# ESP32-H4 register map
Vendor: ESPRESSIF SYSTEMS (SHANGHAI) CO., LTD.; Series: ESP32 H-Series; File version: 1
CPU: RV32IMAC r0p0, little endian, no MPU, no FPU, 0 interrupt priority bits
Address unit: 32 bits
Registers are 32-bit, read-write, reset 0x0 unless marked. A register's access mark holds for its fields unless they carry their own. Offsets are from the block's base; [hi:lo] are bit positions; {n}, {i} and the like mark numbered series.

## LP_AON — LP_AON Peripheral
Base 0x600B2800
{0x0+4i} STORE{i} (i=0..9) — store the software massege{i} in always-on field
  [31:0] LP_AON_STORE{i}
0x28 GPIO_MUX — select the lp io controlled by hp iomux or lp iomux
  [5:0] SEL — select the lp io 0~5 controlled by hp iomux or lp iomux 1: controlled by lp iomux 0: controlled by hp iomux
0x2C GPIO_HOLD0 — configure all io hold
  [31:0] GPIO_HOLD0 — configure io0~28 hold enable,when io in hold status, all io configure and output will be latch , input function is useful
0x30 GPIO_HOLD1 — reserved
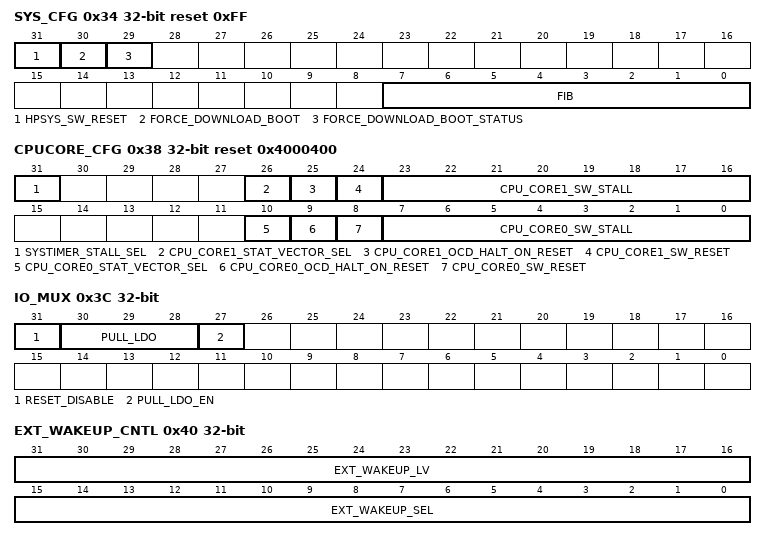
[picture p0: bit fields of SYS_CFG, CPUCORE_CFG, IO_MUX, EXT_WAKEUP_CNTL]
0x34 SYS_CFG access per field reset 0xFF — configure system register
  [31] HPSYS_SW_RESET wo — enable hp system reset by software or not 1: reset 0: no operation
  [30] FORCE_DOWNLOAD_BOOT rw — enable chip entry download mode or not 1: enable 0: no operation
  [29] FORCE_DOWNLOAD_BOOT_STATUS ro — get force download mode status
  [7:0] FIB ro — get fib reg information
0x38 CPUCORE_CFG access per field reset 0x4000400 — configure core reset register
  [31] SYSTIMER_STALL_SEL rw — selete which core run_stall to lp_timer 1: core1 0: core0
  [26] CPU_CORE1_STAT_VECTOR_SEL rw — configure core1 boot address 1: ROM 0: lp memory
  [25] CPU_CORE1_OCD_HALT_ON_RESET rw — reserved
  [24] CPU_CORE1_SW_RESET wo — enable core1 reset by software 1: reset 0: no operation
  [23:16] CPU_CORE1_SW_STALL rw — enable core 1 entry stall status 0x86: entry stall status Others : no operation
  [10] CPU_CORE0_STAT_VECTOR_SEL rw — configure core 0 boot address 1: ROM 0: lp memory
  [9] CPU_CORE0_OCD_HALT_ON_RESET rw — reserved
  [8] CPU_CORE0_SW_RESET wo — enable core 0 reset by software 1: reset 0: no operation
  [7:0] CPU_CORE0_SW_STALL rw — enable cpu 0 entry stall status 0x86: entry stall status Others : no operation
0x3C IO_MUX — configure hp iomux reset bypass
  [31] RESET_DISABLE — bypass hp iomux reset from hp system reset event 1: bypass 0: no operation
  [30:28] PULL_LDO — need_des
  [27] PULL_LDO_EN — need_des
0x40 EXT_WAKEUP_CNTL — configure alwayson external io wakeup
  [31:16] EXT_WAKEUP_LV — select external wakeup io level 1: io high level wakeup 0: io low level wakeup
  [15:0] EXT_WAKEUP_SEL — enable io0~15 bit map use to external wakeup 1: enable 0: disable
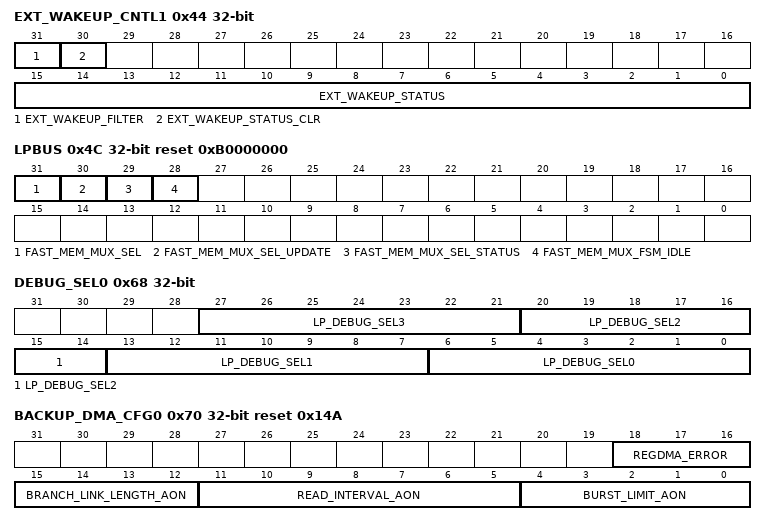
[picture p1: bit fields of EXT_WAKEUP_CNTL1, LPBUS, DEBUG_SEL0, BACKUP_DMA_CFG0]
0x44 EXT_WAKEUP_CNTL1 access per field — configure alwayson external io wakeup
  [31] EXT_WAKEUP_FILTER rw — enable external filter or not 1: enable 0: disable
  [30] EXT_WAKEUP_STATUS_CLR wo — clear external wakeup status 1: clear 0: no operation
  [15:0] EXT_WAKEUP_STATUS ro — get external wakeup status bitmap
0x48 USB — configure usb reset bypass
  [31] RESET_DISABLE — bypass usb reset from hp system reset event 1: bypass 0: no operation
0x4C LPBUS access per field reset 0xB0000000 — Select lp memory bus
  [31] FAST_MEM_MUX_SEL rw — select lp memory bus is high speed mode or low speed mode 1: high speed from hp system ahb 0: low speed from lp system
  [30] FAST_MEM_MUX_SEL_UPDATE wo — enable reg_fast_mem_sel configure 1: enable 0: no operation
  [29] FAST_MEM_MUX_SEL_STATUS ro — get current lp memory bus mode
  [28] FAST_MEM_MUX_FSM_IDLE ro — get current lp memory bus fsm status
0x50 SDIO_ACTIVE reset 0x2800000 — configure sdio act dnum
  [31:22] SDIO_ACT_DNUM — reserved
0x54 SAR_CCT — configure sar cct
  [31:29] SAR2_PWDET_CCT
0x58 MODEM_BUS — configure modem sync bridge
  [31] MODEM_SYNC_BRIDGE_EN — enable modem sync bridge or not 1: enable 0: disable
0x60 SPRAM_CTRL reset 0x2850 — configure lp memory power status
  [31:0] SPRAM_MEM_AUX_CTRL
0x64 SPRF_CTRL reset 0x2850 — configure memory in lp system power status
  [31:0] SPRF_MEM_AUX_CTRL
0x68 DEBUG_SEL0 — reserved
  [7n+6:7n] LP_DEBUG_SEL{n} (n=0..3) — need des
0x6C DEBUG_SEL1 — need des
  [6:0] LP_DEBUG_SEL4
0x70 BACKUP_DMA_CFG0 access per field reset 0x14A — configure regdma always on register
  [18:16] REGDMA_ERROR ro — regdma error code
  [15:12] BRANCH_LINK_LENGTH_AON rw — Set this field to configure link address.
  [11:5] READ_INTERVAL_AON rw — Set this field to configure read registers' interval time in reading mode.
  [4:0] BURST_LIMIT_AON rw — Set this field to configure max value of burst in signle transfer.
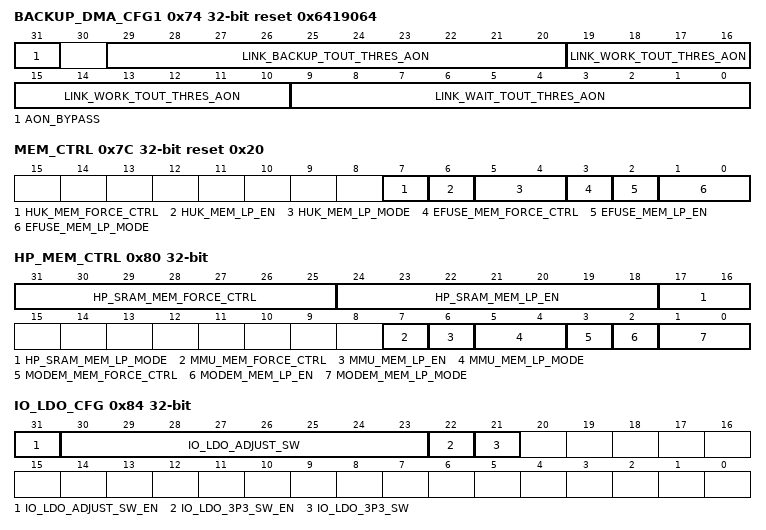
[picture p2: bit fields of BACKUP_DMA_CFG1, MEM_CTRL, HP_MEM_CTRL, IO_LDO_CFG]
0x74 BACKUP_DMA_CFG1 reset 0x6419064 — configure regdma always on register
  [31] AON_BYPASS — reserved
  [29:20] LINK_BACKUP_TOUT_THRES_AON — Set this field to configure maximum waiting time in backup mode.
  [19:10] LINK_WORK_TOUT_THRES_AON — Set this field to configure maximum waiting time in waiting mode.
  [9:0] LINK_WAIT_TOUT_THRES_AON — Set this field to configure the number of consecutive links of link list.
0x78 BACKUP_DMA_CFG2 — configure regdma always on register
  [31:0] LINK_ADDR_AON — Set this field to configure link address.
0x7C MEM_CTRL reset 0x20 — configure rmemory power in lp system register
  [7] HUK_MEM_FORCE_CTRL — Set this bit to force software control huk memory, disbale hardware control.
  [6] HUK_MEM_LP_EN — Set this bit to power down huk memory.
  [5:4] HUK_MEM_LP_MODE — Configures huk memory low power mode in low power stage.\\ 0: deep sleep\\ 1: light sleep\\ 2(default): shut down\\ 3: disable low power stage\\
  [3] EFUSE_MEM_FORCE_CTRL — Set this bit to force software control efuse memory, disbale hardware control.
  [2] EFUSE_MEM_LP_EN — Set this bit to power down efuse memory.
  [1:0] EFUSE_MEM_LP_MODE — Configures efuse memory low power mode in low power stage.\\ 0(default): deep sleep\\ 1: light sleep\\ 2: shut down\\ 3: disable low power stage\\
0x80 HP_MEM_CTRL — configure rmemory power in lp system register
  [31:25] HP_SRAM_MEM_FORCE_CTRL — Set this bit to force software control hp_sram memory, disbale hardware control.
  [24:18] HP_SRAM_MEM_LP_EN — Set this bit to power down hp_sram memory.
  [17:16] HP_SRAM_MEM_LP_MODE — Configures hp_sram memory low power mode in low power stage.\\ 0(default): deep sleep\\ 1: light sleep\\ 2: shut down\\ 3: disable low power stage\\
  [7] MMU_MEM_FORCE_CTRL — Set this bit to force software control mmu memory, disbale hardware control.
  [6] MMU_MEM_LP_EN — Set this bit to power down mmu memory.
  [5:4] MMU_MEM_LP_MODE — Configures mmu memory low power mode in low power stage.\\ 0: deep sleep\\ 1: light sleep\\ 2(default): shut down\\ 3: disable low power stage\\
  [3] MODEM_MEM_FORCE_CTRL — Set this bit to force software control modem memory, disbale hardware control.
  [2] MODEM_MEM_LP_EN — Set this bit to power down modem memory.
  [1:0] MODEM_MEM_LP_MODE — Configures modem memory low power mode in low power stage.\\ 0(default): deep sleep\\ 1: light sleep\\ 2: shut down\\ 3: disable low power stage\\
0x84 IO_LDO_CFG — need_des
  [31] IO_LDO_ADJUST_SW_EN — need_des
  [30:23] IO_LDO_ADJUST_SW — need_des
  [22] IO_LDO_3P3_SW_EN — need_des
  [21] IO_LDO_3P3_SW — need_des
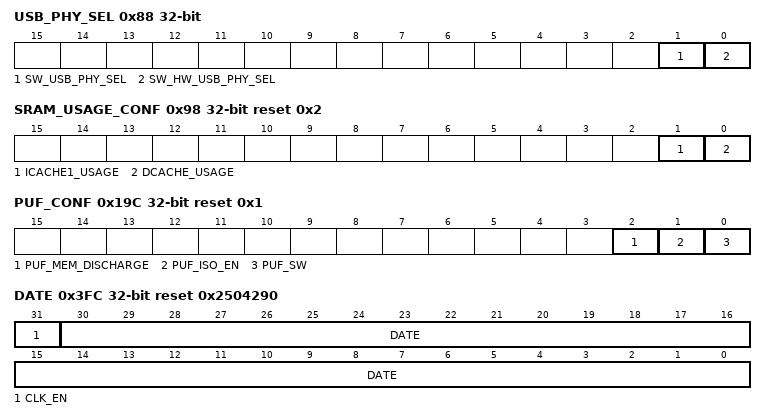
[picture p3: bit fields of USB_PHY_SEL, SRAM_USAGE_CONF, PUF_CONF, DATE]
0x88 USB_PHY_SEL — need des
  [1] SW_USB_PHY_SEL — when LP_AON_SW_HW_USB_PHY_SEL is configured as 1 , a register value of 0 means no swapping the phy
  [0] SW_HW_USB_PHY_SEL — 0: the control bit of efuse will determine whether to exchange usb0/1_phy,1: LP_AON_SW_USB_PHY_SEL will determine whether to exchange usb0/1_phy
0x98 SRAM_USAGE_CONF reset 0x2 — HP memory usage configuration register
  [1] ICACHE1_USAGE — hp system memory is splited to 7 layers(Layer0 ~ Layer6) in total, this field is used to control the last layer(Layer6) usage. 0: cpu use hp-memory. 1: icache1 use hp-mmory. \\ By default, icache1 is not disabled, and the last layer memory blongs to icache1. Typically users can set this bit to 0 to disable icache1 in boot-loader.
  [0] DCACHE_USAGE — hp system memory is splited to 7 layers(Layer0 ~ Layer6) in total, this field is used to control the first layer(Layer0) usage. 0: cpu use hp-memory. 1: dcache use hp-mmory. By default, dcache is closed, and typically users can enable dcache after boot-loader, but before user's BIN start runing.
0x19C PUF_CONF reset 0x1 — PUF mem control config register
  [2] PUF_MEM_DISCHARGE — discharge signal for puf mem
  [1] PUF_ISO_EN — iso enable signal for puf mem
  [0] PUF_SW — puf mem power switch control signal
0x3FC DATE reset 0x2504290 — reserved
  [31] CLK_EN — version register
  [30:0] DATE — version register
